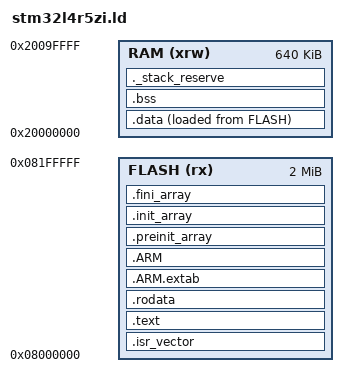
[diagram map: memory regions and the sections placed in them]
/*
 * Linker script for the STM32L4R5ZI flight image (FINDINGS_REGISTER SW-01).
 *
 * Memory (ST CMSIS header stm32l4r5xx.h): 2 MB flash at 0x08000000; SRAM1
 * (192 KB) at 0x20000000, SRAM2 (64 KB) aliased at 0x20030000 and SRAM3
 * (384 KB) at 0x20040000, contiguous: 640 KB from 0x20000000.
 *
 * No heap: the flight software allocates nothing at run time. The stack
 * grows down from the top of RAM; the link fails if .data, .bss and the
 * minimum stack do not fit.
 *
 * The OBC design's flash partition (code, golden image, data) is for the
 * bootloader, which does not exist yet; this image is linked for the start
 * of flash.
 */

ENTRY(Reset_Handler)

MEMORY
{
    FLASH (rx)  : ORIGIN = 0x08000000, LENGTH = 2048K
    RAM   (xrw) : ORIGIN = 0x20000000, LENGTH = 640K
}

_estack = ORIGIN(RAM) + LENGTH(RAM);
_min_stack_size = 0x4000;   /* 16 KB */

SECTIONS
{
    .isr_vector :
    {
        . = ALIGN(4);
        KEEP(*(.isr_vector))
        . = ALIGN(4);
    } > FLASH

    .text :
    {
        . = ALIGN(4);
        *(.text)
        *(.text*)
        *(.glue_7)
        *(.glue_7t)
        KEEP(*(.init))
        KEEP(*(.fini))
        . = ALIGN(4);
        _etext = .;
    } > FLASH

    .rodata :
    {
        . = ALIGN(4);
        *(.rodata)
        *(.rodata*)
        . = ALIGN(4);
    } > FLASH

    .ARM.extab : { *(.ARM.extab* .gnu.linkonce.armextab.*) } > FLASH
    .ARM :
    {
        __exidx_start = .;
        *(.ARM.exidx*)
        __exidx_end = .;
    } > FLASH

    .preinit_array :
    {
        PROVIDE_HIDDEN(__preinit_array_start = .);
        KEEP(*(.preinit_array*))
        PROVIDE_HIDDEN(__preinit_array_end = .);
    } > FLASH
    .init_array :
    {
        PROVIDE_HIDDEN(__init_array_start = .);
        KEEP(*(SORT(.init_array.*)))
        KEEP(*(.init_array*))
        PROVIDE_HIDDEN(__init_array_end = .);
    } > FLASH
    .fini_array :
    {
        PROVIDE_HIDDEN(__fini_array_start = .);
        KEEP(*(SORT(.fini_array.*)))
        KEEP(*(.fini_array*))
        PROVIDE_HIDDEN(__fini_array_end = .);
    } > FLASH

    _sidata = LOADADDR(.data);

    .data :
    {
        . = ALIGN(4);
        _sdata = .;
        *(.data)
        *(.data*)
        . = ALIGN(4);
        _edata = .;
    } > RAM AT> FLASH

    .bss (NOLOAD) :
    {
        . = ALIGN(4);
        _sbss = .;
        __bss_start__ = _sbss;
        *(.bss)
        *(.bss*)
        *(COMMON)
        . = ALIGN(4);
        _ebss = .;
        __bss_end__ = _ebss;
    } > RAM

    /* Reserves the minimum stack; the link fails if RAM overflows */
    ._stack_reserve (NOLOAD) :
    {
        . = ALIGN(8);
        . = . + _min_stack_size;
        . = ALIGN(8);
    } > RAM

    .ARM.attributes 0 : { *(.ARM.attributes) }
}
